# ATSAMV70N19 register map
Vendor: Microchip Technology; File version: 0
CPU: CM7 r1p1, little endian, no MPU, no FPU, 0x3 interrupt priority bits, 0x0 interrupts
Registers are 32-bit, read-write, reset 0x0 unless marked. A register's access mark holds for its fields unless they carry their own. Offsets are from the block's base; [hi:lo] are bit positions; {n}, {i} and the like mark numbered series; 'fields as' and 'values as' point back to an identical list.

## MLB — Media LB
Base 0x40068000; register names take the prefix MLB_
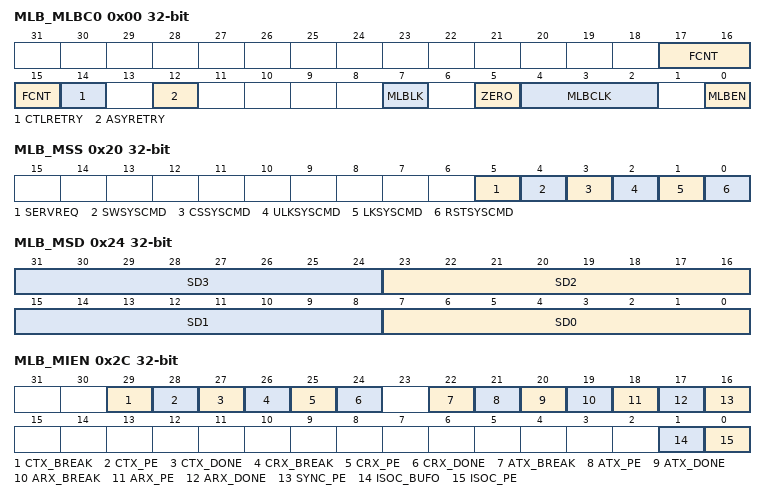
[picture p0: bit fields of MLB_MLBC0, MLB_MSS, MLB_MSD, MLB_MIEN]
0x00 MLB_MLBC0 — MediaLB Control 0 Register
  [17:15] FCNT — The number of frames per sub-buffer for synchronous channels
    0=_1_FRAME (1 frame per sub-buffer (Operation is the same as Standard mode.)); 1=_2_FRAMES (2 frames per sub-buffer); 2=_4_FRAMES (4 frames per sub-buffer); 3=_8_FRAMES (8 frames per sub-buffer); 4=_16_FRAMES (16 frames per sub-buffer); 5=_32_FRAMES (32 frames per sub-buffer); 6=_64_FRAMES (64 frames per sub-buffer)
  [14] CTLRETRY — Control Tx Packet Retry
  [12] ASYRETRY — Asynchronous Tx Packet Retry
  [7] MLBLK — MediaLB Lock Status (read-only)
  [5] ZERO — Must be Written to 0
  [4:2] MLBCLK — MLBCLK (MediaLB clock) speed select
    0=_256_FS (256xFs (for MLBPEN = 0)); 1=_512_FS (512xFs (for MLBPEN = 0)); 2=_1024_FS (1024xFs (for MLBPEN = 0))
  [0] MLBEN — MediaLB Enable
0x0C MLB_MS0 — MediaLB Channel Status 0 Register
  [31:0] MCS — MediaLB Channel Status [31:0] (cleared by writing a 0)
0x14 MLB_MS1 — MediaLB Channel Status1 Register
  [31:0] MCS — MediaLB Channel Status [63:32] (cleared by writing a 0)
0x20 MLB_MSS — MediaLB System Status Register
  [5] SERVREQ — Service Request Enabled
  [4] SWSYSCMD — Software System Command Detected in the System Quadlet (cleared by writing a 0)
  [3] CSSYSCMD — Channel Scan System Command Detected in the System Quadlet (cleared by writing a 0)
  [2] ULKSYSCMD — Network Unlock System Command Detected in the System Quadlet (cleared by writing a 0)
  [1] LKSYSCMD — Network Lock System Command Detected in the System Quadlet (cleared by writing a 0)
  [0] RSTSYSCMD — Reset System Command Detected in the System Quadlet (cleared by writing a 0)
0x24 MLB_MSD ro — MediaLB System Data Register
  [8n+7:8n] SD{n} (n=0..3) — System Data (Byte {n})
0x2C MLB_MIEN — MediaLB Interrupt Enable Register
  [29] CTX_BREAK — Control Tx Break Enable
  [28] CTX_PE — Control Tx Protocol Error Enable
  [27] CTX_DONE — Control Tx Packet Done Enable
  [26] CRX_BREAK — Control Rx Break Enable
  [25] CRX_PE — Control Rx Protocol Error Enable
  [24] CRX_DONE — Control Rx Packet Done Enable
  [22] ATX_BREAK — Asynchronous Tx Break Enable
  [21] ATX_PE — Asynchronous Tx Protocol Error Enable
  [20] ATX_DONE — Asynchronous Tx Packet Done Enable
  [19] ARX_BREAK — Asynchronous Rx Break Enable
  [18] ARX_PE — Asynchronous Rx Protocol Error Enable
  [17] ARX_DONE — Asynchronous Rx Done Enable
  [16] SYNC_PE — Synchronous Protocol Error Enable
  [1] ISOC_BUFO — Isochronous Rx Buffer Overflow Enable
  [0] ISOC_PE — Isochronous Rx Protocol Error Enable
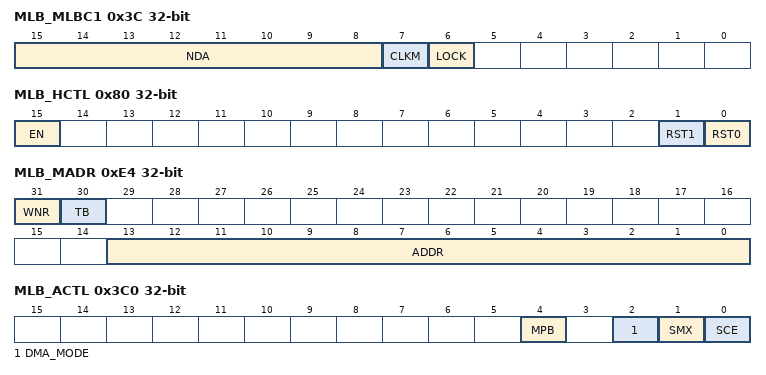
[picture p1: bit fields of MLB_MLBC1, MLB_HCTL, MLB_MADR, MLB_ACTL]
0x3C MLB_MLBC1 — MediaLB Control 1 Register
  [15:8] NDA — Node Device Address
  [7] CLKM — MediaLB Clock Missing Status (cleared by writing a 0)
  [6] LOCK — MediaLB Lock Error Status (cleared by writing a 0)
0x80 MLB_HCTL — HBI Control Register
  [15] EN — HBI Enable
  [1] RST1 — Address Generation Unit 1 Software Reset
  [0] RST0 — Address Generation Unit 0 Software Reset
0x88 MLB_HCMR[0] — HBI Channel Mask 0 Register 0
  [31:0] CHM — Bitwise Channel Mask Bit [31:0]
0x8C MLB_HCMR[1] — HBI Channel Mask 0 Register 0
  [31:0] CHM — Bitwise Channel Mask Bit [31:0]
0x90 MLB_HCER[0] ro — HBI Channel Error 0 Register 0
  [31:0] CERR — Bitwise Channel Error Bit [31:0]
0x94 MLB_HCER[1] ro — HBI Channel Error 0 Register 0
  [31:0] CERR — Bitwise Channel Error Bit [31:0]
0x98 MLB_HCBR[0] ro — HBI Channel Busy 0 Register 0
  [31:0] CHB — Bitwise Channel Busy Bit [31:0]
0x9C MLB_HCBR[1] ro — HBI Channel Busy 0 Register 0
  [31:0] CHB — Bitwise Channel Busy Bit [31:0]
{0xC0+4i} MLB_MDAT[{i}] (i=0..3) — MIF Data 0 Register 0
  [31:0] DATA — CRT or DBR Data
{0xD0+4i} MLB_MDWE[{i}] (i=0..3) — MIF Data Write Enable 0 Register 0
  [31:0] MASK — Bitwise Write Enable for CTR Data - bits[31:0]
0xE0 MLB_MCTL — MIF Control Register
  [0] XCMP — Transfer Complete (Write 0 to Clear)
0xE4 MLB_MADR — MIF Address Register
  [31] WNR — Write-Not-Read Selection
  [30] TB — Target Location Bit
    0=CTR (Selects CTR); 1=DBR (Selects DBR)
  [13:0] ADDR — CTR or DBR Address
0x3C0 MLB_ACTL — AHB Control Register
  [4] MPB — DMA Packet Buffering Mode
    0=SINGLE_PACKET (Single-packet mode); 1=MULTIPLE_PACKET (Multiple-packet mode)
  [2] DMA_MODE
  [1] SMX — AHB Interrupt Mux Enable
  [0] SCE — Software Clear Enable
0x3D0 MLB_ACSR[0] — AHB Channel Status 0 Register 0
  [31:0] CHS — Interrupt Status for Logical Channels [31:0] (cleared by writing a 1)
0x3D4 MLB_ACSR[1] — AHB Channel Status 0 Register 0
  fields as MLB_ACSR[0]
0x3D8 MLB_ACMR[0] — AHB Channel Mask 0 Register 0
  [31:0] CHM — Bitwise Channel Mask Bits 31 to 0
0x3DC MLB_ACMR[1] — AHB Channel Mask 0 Register 0
  [31:0] CHM — Bitwise Channel Mask Bits 31 to 0
